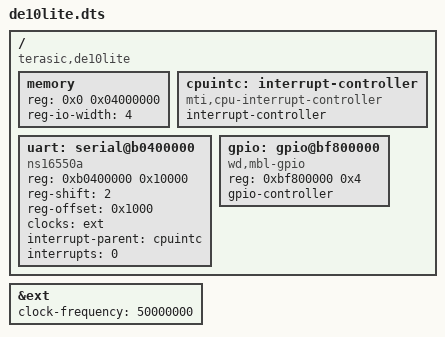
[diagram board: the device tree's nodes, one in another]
/dts-v1/;

#include <dt-bindings/gpio/gpio.h>

#include "microAptiv.dtsi"

/ {
	compatible = "terasic,de10lite";

	memory {
		device_type = "memory";
		reg = <0x0 0x04000000>;
		reg-io-width = <4>;
	};

	cpuintc: interrupt-controller {
		#address-cells = <0>;
		#interrupt-cells = <1>;
		interrupt-controller;
		compatible = "mti,cpu-interrupt-controller";
	};

	uart: serial@b0400000 {
		compatible = "ns16550a";
		reg = <0xb0400000 0x10000>;

		reg-shift = <2>;
		reg-offset = <0x1000>;

		clocks	= <&ext>;

		interrupt-parent = <&cpuintc>;
		interrupts = <0>;
	};

	gpio: gpio@bf800000 {
		compatible = "wd,mbl-gpio";
		reg = <0xbf800000 0x4>;

		reg-names = "dat";
		gpio-controller;
		#gpio-cells = <2>;
	} ;
};

&ext {
	clock-frequency = <50000000>;
};
